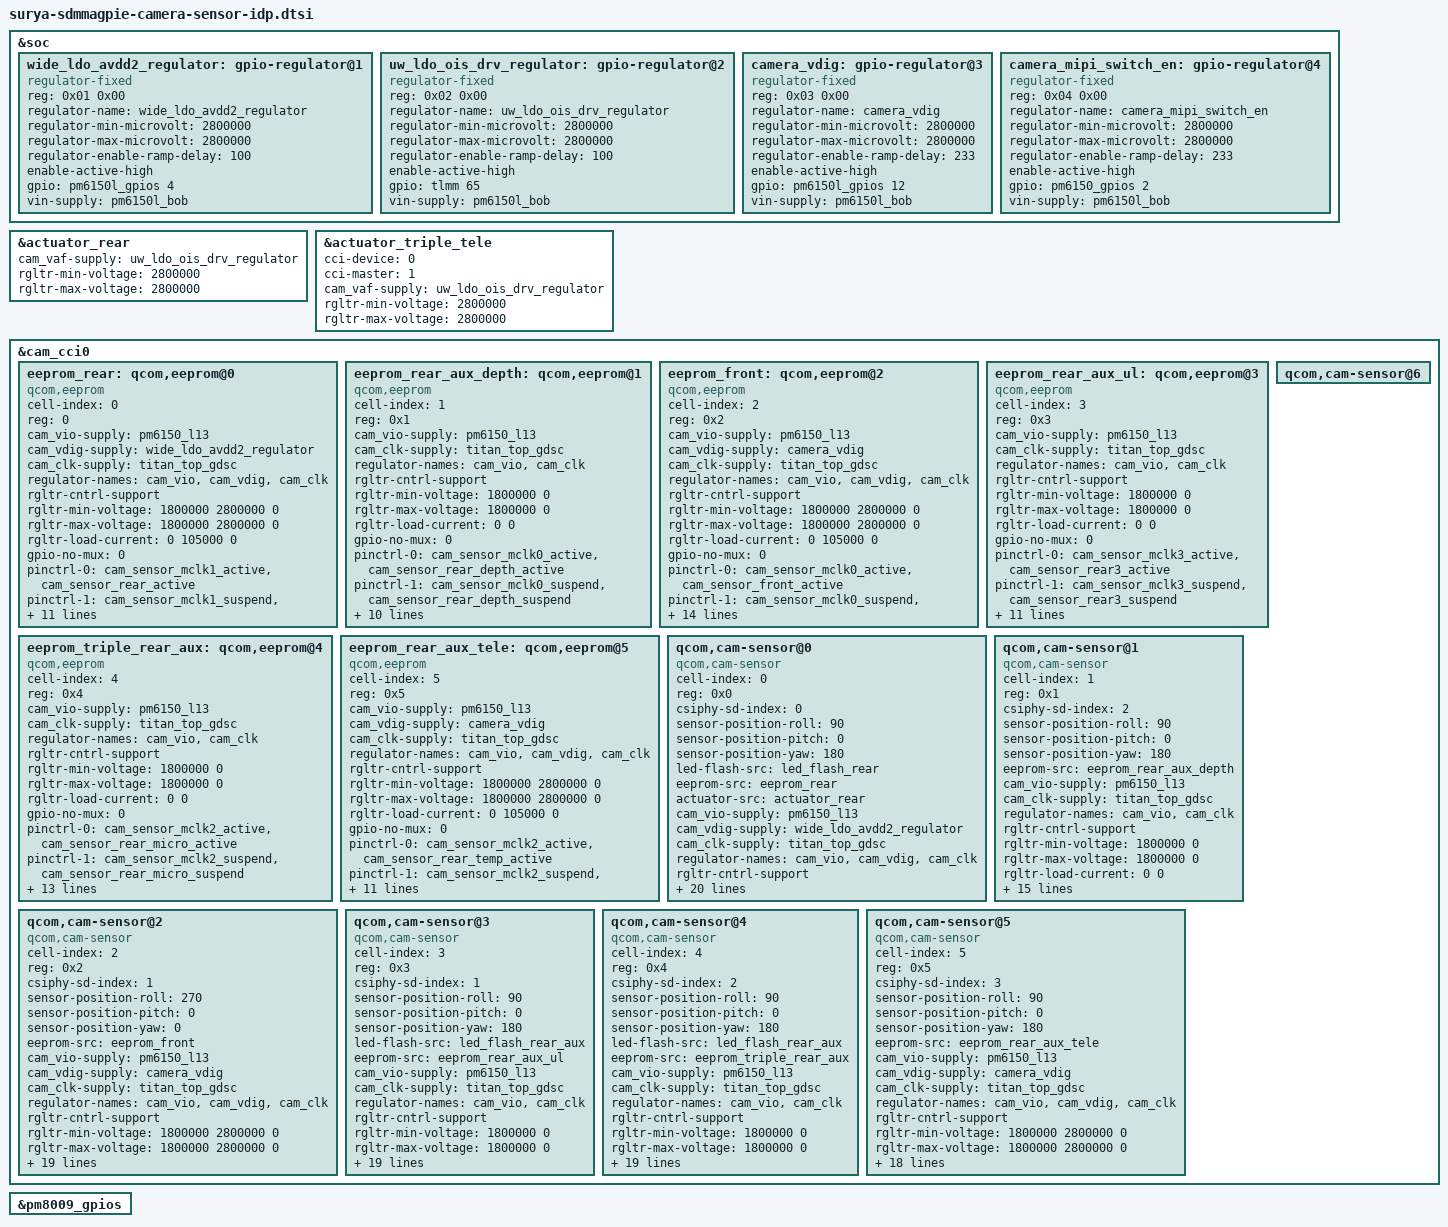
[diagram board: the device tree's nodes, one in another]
&soc {
	wide_ldo_avdd2_regulator: gpio-regulator@1 { /* AVDD2 1.8V */
		compatible = "regulator-fixed";
		reg = <0x01 0x00>;
		regulator-name = "wide_ldo_avdd2_regulator";
		regulator-min-microvolt = <2800000>;
		regulator-max-microvolt = <2800000>;
		regulator-enable-ramp-delay = <100>;
		enable-active-high;
		gpio = <&pm6150l_gpios 4 0>;
		vin-supply = <&pm6150l_bob>; /* pm6150l_s8 */
	};

	uw_ldo_ois_drv_regulator: gpio-regulator@2 { /* drvVDD 2.8V */
		compatible = "regulator-fixed";
		reg = <0x02 0x00>;
		regulator-name = "uw_ldo_ois_drv_regulator";
		regulator-min-microvolt = <2800000>;
		regulator-max-microvolt = <2800000>;
		regulator-enable-ramp-delay = <100>;
		enable-active-high;
		gpio = <&tlmm 65 0>;
		vin-supply = <&pm6150l_bob>;
	};

	camera_vdig: gpio-regulator@3 {
		compatible = "regulator-fixed";
		reg = <0x03 0x00>;
		regulator-name = "camera_vdig";
		regulator-min-microvolt = <2800000>;
		regulator-max-microvolt = <2800000>;
		regulator-enable-ramp-delay = <233>;
		enable-active-high;
		gpio = <&pm6150l_gpios 12 0>;
		vin-supply = <&pm6150l_bob>;
	};

	camera_mipi_switch_en: gpio-regulator@4 {
		compatible = "regulator-fixed";
		reg = <0x04 0x00>;
		regulator-name = "camera_mipi_switch_en";
		regulator-min-microvolt = <2800000>;
		regulator-max-microvolt = <2800000>;
		regulator-enable-ramp-delay = <233>;
		enable-active-high;
		gpio = <&pm6150_gpios 2 0>;
		vin-supply = <&pm6150l_bob>;
	};
};

&actuator_rear {
	cam_vaf-supply = <&uw_ldo_ois_drv_regulator>;
	rgltr-min-voltage = <2800000>;
	rgltr-max-voltage = <2800000>;
};

&actuator_triple_tele {
	cci-device = <0>;
	cci-master = <1>;
	cam_vaf-supply = <&uw_ldo_ois_drv_regulator>;
	rgltr-min-voltage = <2800000>;
	rgltr-max-voltage = <2800000>;
};

&cam_cci0 {
	/delete-node/ qcom,eeprom@0;
	/delete-node/ qcom,eeprom@1;
	/delete-node/ qcom,eeprom@2;
	/delete-node/ qcom,eeprom@3;
	/delete-node/ qcom,eeprom@4;

	eeprom_rear: qcom,eeprom@0 {
		cell-index = <0>;
		reg = <0>;
		compatible = "qcom,eeprom";
		cam_vio-supply = <&pm6150_l13>; /* iovdd 1.8v */
		cam_vdig-supply = <&wide_ldo_avdd2_regulator>; /* dvdd 1.1v */
		cam_clk-supply = <&titan_top_gdsc>;
		regulator-names = "cam_vio", "cam_vdig", "cam_clk";
		rgltr-cntrl-support;
		rgltr-min-voltage = <1800000 2800000 0>;
		rgltr-max-voltage = <1800000 2800000 0>;
		rgltr-load-current = <0 105000 0>;
		gpio-no-mux = <0>;
		pinctrl-names = "cam_default", "cam_suspend";
		pinctrl-0 = <&cam_sensor_mclk1_active
				&cam_sensor_rear_active>;
		pinctrl-1 = <&cam_sensor_mclk1_suspend
				&cam_sensor_rear_suspend>;
		gpios = <&tlmm 14 0>,
			<&tlmm 25 0>;
		gpio-reset = <1>;
		gpio-req-tbl-num = <0 1>;
		gpio-req-tbl-flags = <1 0>;
		gpio-req-tbl-label = "CAMIF_MCLK1",
					"CAM_RESET0";
		sensor-mode = <0>;
		cci-master = <0>;
		status = "ok";
		clocks = <&clock_camcc CAM_CC_MCLK1_CLK>;
		clock-names = "cam_clk";
		clock-cntl-level = "turbo";
		clock-rates = <19200000>;
	};

	eeprom_rear_aux_depth: qcom,eeprom@1 {
		cell-index = <1>;
		reg = <0x1>;
		compatible = "qcom,eeprom";
		cam_vio-supply = <&pm6150_l13>;
		cam_clk-supply = <&titan_top_gdsc>;
		regulator-names = "cam_vio", "cam_clk";
		rgltr-cntrl-support;
		rgltr-min-voltage = <1800000 0>;
		rgltr-max-voltage = <1800000 0>;
		rgltr-load-current = <0 0>;
		gpio-no-mux = <0>;
		pinctrl-names = "cam_default", "cam_suspend";
		pinctrl-0 = <&cam_sensor_mclk0_active
				&cam_sensor_rear_depth_active>;
		pinctrl-1 = <&cam_sensor_mclk0_suspend
				&cam_sensor_rear_depth_suspend>;
		gpios = <&tlmm 13 0>,
				<&tlmm 93 0>;
		gpio-reset = <1>;
		gpio-req-tbl-num = <0 1>;
		gpio-req-tbl-flags = <1 0>;
		gpio-req-tbl-label = "CAMIF_MCLK0",
					"CAM_RESET1";
		sensor-mode = <0>;
		cci-master = <1>;
		status = "ok";
		clocks = <&clock_camcc CAM_CC_MCLK0_CLK>;
		clock-names = "cam_clk";
		clock-cntl-level = "turbo";
		clock-rates = <19200000>;
	};

	eeprom_front: qcom,eeprom@2 {
		cell-index = <2>;
		reg = <0x2>;
		compatible = "qcom,eeprom";
		cam_vio-supply = <&pm6150_l13>;
		cam_vdig-supply = <&camera_vdig>;
		cam_clk-supply = <&titan_top_gdsc>;
		regulator-names = "cam_vio",  "cam_vdig", "cam_clk";
		rgltr-cntrl-support;
		rgltr-min-voltage = <1800000 2800000 0>;
		rgltr-max-voltage = <1800000 2800000 0>;
		rgltr-load-current = <0 105000 0>;
		gpio-no-mux = <0>;
		pinctrl-names = "cam_default", "cam_suspend";
		pinctrl-0 = <&cam_sensor_mclk0_active
				&cam_sensor_front_active>;
		pinctrl-1 = <&cam_sensor_mclk0_suspend
				&cam_sensor_front_suspend>;
		gpios = <&tlmm 13 0>,
			<&tlmm 23 0>,
			<&pm6150_gpios 3 0>;
		gpio-reset = <1>;
		gpio-standby = <2>;
		gpio-req-tbl-num = <0 1 2>;
		gpio-req-tbl-flags = <1 0 0>;
		gpio-req-tbl-label = "CAMIF_MCLK0",
					"CAM_RESET4",
					"CAM_SEL";
		sensor-mode = <0>;
		cci-device = <0>;
		cci-master = <1>;
		status = "ok";
		clocks = <&clock_camcc CAM_CC_MCLK0_CLK>;
		clock-names = "cam_clk";
		clock-cntl-level = "turbo";
		clock-rates = <19200000>;
	};

	eeprom_rear_aux_ul: qcom,eeprom@3 {
		cell-index = <3>;
		reg = <0x3>;
		compatible = "qcom,eeprom";
		cam_vio-supply = <&pm6150_l13>;
		cam_clk-supply = <&titan_top_gdsc>;
		regulator-names = "cam_vio", "cam_clk";
		rgltr-cntrl-support;
		rgltr-min-voltage = <1800000 0>;
		rgltr-max-voltage = <1800000 0>;
		rgltr-load-current = <0 0>;
		gpio-no-mux = <0>;
		pinctrl-names = "cam_default", "cam_suspend";
		pinctrl-0 = <&cam_sensor_mclk3_active
				&cam_sensor_rear3_active>;
		pinctrl-1 = <&cam_sensor_mclk3_suspend
				&cam_sensor_rear3_suspend>;
		gpios = <&tlmm 16 0>,
			<&tlmm 24 0>;
		gpio-reset = <1>;
		gpio-req-tbl-num = <0 1>;
		gpio-req-tbl-flags = <1 0>;
		gpio-req-tbl-label = "CAMIF_MCLK13",
					"CAM_RESET3";
		sensor-mode = <0>;
		cci-device = <1>;
		cci-master = <0>;
		status = "ok";
		clocks = <&clock_camcc CAM_CC_MCLK3_CLK>;
		clock-names = "cam_clk";
		clock-cntl-level = "turbo";
		clock-rates = <19200000>;
	};

	eeprom_triple_rear_aux: qcom,eeprom@4 {
		cell-index = <4>;
		reg = <0x4>;
		compatible = "qcom,eeprom";
		cam_vio-supply = <&pm6150_l13>;
		cam_clk-supply = <&titan_top_gdsc>;
		regulator-names = "cam_vio", "cam_clk";
		rgltr-cntrl-support;
		rgltr-min-voltage = <1800000 0>;
		rgltr-max-voltage = <1800000 0>;
		rgltr-load-current = <0 0>;
		gpio-no-mux = <0>;
		pinctrl-names = "cam_default", "cam_suspend";
		pinctrl-0 = <&cam_sensor_mclk2_active
				&cam_sensor_rear_micro_active>;
		pinctrl-1 = <&cam_sensor_mclk2_suspend
				&cam_sensor_rear_micro_suspend>;
		gpios = <&tlmm 15 0>,
			<&tlmm 64 0>,
			<&tlmm 57 0>;
		gpio-reset = <1>;
		gpio-standby = <2>;
		gpio-req-tbl-num = <0 1 2>;
		gpio-req-tbl-flags = <1 0 0>;
		gpio-req-tbl-label = "CAMIF_MCLK2",
					"CAM_RESET1",
					"CAM_CHIP_EN";
		sensor-mode = <0>;
		cci-device = <1>;
		cci-master = <0>;
		status = "ok";
		clocks = <&clock_camcc CAM_CC_MCLK2_CLK>;
		clock-names = "cam_clk";
		clock-cntl-level = "turbo";
		clock-rates = <19200000>;
	};

	eeprom_rear_aux_tele: qcom,eeprom@5 {
		cell-index = <5>;
		reg = <0x5>;
		compatible = "qcom,eeprom";
		cam_vio-supply = <&pm6150_l13>;
		cam_vdig-supply = <&camera_vdig>;
		cam_clk-supply = <&titan_top_gdsc>;
		regulator-names = "cam_vio", "cam_vdig", "cam_clk";
		rgltr-cntrl-support;
		rgltr-min-voltage = <1800000 2800000 0>;
		rgltr-max-voltage = <1800000 2800000 0>;
		rgltr-load-current = <0 105000 0>;
		gpio-no-mux = <0>;
		pinctrl-names = "cam_default", "cam_suspend";
		pinctrl-0 = <&cam_sensor_mclk2_active
				&cam_sensor_rear_temp_active>;
		pinctrl-1 = <&cam_sensor_mclk2_suspend
				&cam_sensor_rear_temp_suspend>;
		gpios = <&tlmm 15 0>,
			<&tlmm 72 0>;
		gpio-reset = <1>;
		gpio-req-tbl-num = <0 1>;
		gpio-req-tbl-flags = <1 0>;
		gpio-req-tbl-label = "CAMIF_MCLK2",
					"CAM_RESET_N";
		sensor-mode = <0>;
		cci-master = <1>;
		status = "ok";
		clocks = <&clock_camcc CAM_CC_MCLK2_CLK>;
		clock-names = "cam_clk";
		clock-cntl-level = "turbo";
		clock-rates = <19200000>;
	};


	/delete-node/ qcom,cam-sensor@0;
	/delete-node/ qcom,cam-sensor@1;
	/delete-node/ qcom,cam-sensor@2;
	/delete-node/ qcom,cam-sensor@3;
	/delete-node/ qcom,cam-sensor@4;
	/delete-node/ qcom,cam-sensor@5;

	qcom,cam-sensor@0 {
		cell-index = <0>;
		compatible = "qcom,cam-sensor";
		reg = <0x0>;
		csiphy-sd-index = <0>;
		sensor-position-roll = <90>;
		sensor-position-pitch = <0>;
		sensor-position-yaw = <180>;
		led-flash-src = <&led_flash_rear>;
		eeprom-src = <&eeprom_rear>;
		actuator-src = <&actuator_rear>;
		cam_vio-supply = <&pm6150_l13>; /* iovdd 1.8v */
		cam_vdig-supply = <&wide_ldo_avdd2_regulator>; /* dvdd 1.1v */
		cam_clk-supply = <&titan_top_gdsc>;
		regulator-names = "cam_vio", "cam_vdig", "cam_clk";
		rgltr-cntrl-support;
		rgltr-min-voltage = <1800000 2800000 0>;
		rgltr-max-voltage = <1800000 2800000 0>;
		rgltr-load-current = <0 105000 0>;
		gpio-no-mux = <0>;
		pinctrl-names = "cam_default", "cam_suspend";
		pinctrl-0 = <&cam_sensor_mclk1_active
				&cam_sensor_rear_active>;
		pinctrl-1 = <&cam_sensor_mclk1_suspend
				&cam_sensor_rear_suspend>;
		gpios = <&tlmm 14 0>,
			<&tlmm 25 0>,
			<&tlmm 66 0>;
		gpio-reset = <1>;
		gpio-standby = <2>;
		gpio-req-tbl-num = <0 1 2>;
		gpio-req-tbl-flags = <1 0 0>;
		gpio-req-tbl-label = "CAMIF_MCLK1",
					"CAM_RESET0",
					"CAM_STANDBY"; /* vafs */
		sensor-mode = <0>;
		cci-master = <0>;
		status = "ok";
		clocks = <&clock_camcc CAM_CC_MCLK1_CLK>;
		clock-names = "cam_clk";
		clock-cntl-level = "turbo";
		clock-rates = <19200000>;
	};

	qcom,cam-sensor@1 {
		cell-index = <1>;
		compatible = "qcom,cam-sensor";
		reg = <0x1>;
		csiphy-sd-index = <2>;
		sensor-position-roll = <90>;
		sensor-position-pitch = <0>;
		sensor-position-yaw = <180>;
		eeprom-src = <&eeprom_rear_aux_depth>;
		cam_vio-supply = <&pm6150_l13>;
		cam_clk-supply = <&titan_top_gdsc>;
		regulator-names = "cam_vio",
			"cam_clk";
		rgltr-cntrl-support;
		rgltr-min-voltage = <1800000 0>;
		rgltr-max-voltage = <1800000 0>;
		rgltr-load-current = <0 0>;
		gpio-no-mux = <0>;
		pinctrl-names = "cam_default", "cam_suspend";
		pinctrl-0 = <&cam_sensor_mclk0_active
				&cam_sensor_rear_depth_active>;
		pinctrl-1 = <&cam_sensor_mclk0_suspend
				&cam_sensor_rear_depth_suspend>;
		gpios = <&tlmm 13 0>,
				<&tlmm 93 0>;
		gpio-reset = <1>;
		gpio-req-tbl-num = <0 1>;
		gpio-req-tbl-flags = <1 0>;
		gpio-req-tbl-label = "CAMIF_MCLK0",
					"CAM_RESET1";
		sensor-mode = <0>;
		cci-master = <1>;
		status = "ok";
		clocks = <&clock_camcc CAM_CC_MCLK0_CLK>;
		clock-names = "cam_clk";
		clock-cntl-level = "turbo";
		clock-rates = <19200000>;
	};

	qcom,cam-sensor@2 {
		cell-index = <2>;
		compatible = "qcom,cam-sensor";
		reg = <0x2>;
		csiphy-sd-index = <1>;
		sensor-position-roll = <270>;
		sensor-position-pitch = <0>;
		sensor-position-yaw = <0>;
		eeprom-src = <&eeprom_front>;
		cam_vio-supply = <&pm6150_l13>;
		cam_vdig-supply = <&camera_vdig>; /* gpio12 */
		cam_clk-supply = <&titan_top_gdsc>;
		regulator-names = "cam_vio",  "cam_vdig", "cam_clk";
		rgltr-cntrl-support;
		rgltr-min-voltage = <1800000 2800000 0>;
		rgltr-max-voltage = <1800000 2800000 0>;
		rgltr-load-current = <0 105000 0>;
		gpio-no-mux = <0>;
		pinctrl-names = "cam_default", "cam_suspend";
		pinctrl-0 = <&cam_sensor_mclk0_active
				&cam_sensor_front_active>;
		pinctrl-1 = <&cam_sensor_mclk0_suspend
				&cam_sensor_front_suspend>;
		gpios = <&tlmm 13 0>,
			<&tlmm 23 0>,
			<&pm6150_gpios 3 0>;
		gpio-reset = <1>;
		gpio-standby = <2>;
		gpio-req-tbl-num = <0 1 2>;
		gpio-req-tbl-flags = <1 0 0>;
		gpio-req-tbl-label = "CAMIF_MCLK0",
					"CAM_RESET4",
					"CAM_SEL";
		sensor-mode = <0>;
		cci-device = <0>;
		cci-master = <1>;
		status = "ok";
		clocks = <&clock_camcc CAM_CC_MCLK0_CLK>;
		clock-names = "cam_clk";
		clock-cntl-level = "turbo";
		clock-rates = <19200000>;
	};

	qcom,cam-sensor@3 {
		cell-index = <3>;
		compatible = "qcom,cam-sensor";
		reg = <0x3>;
		csiphy-sd-index = <1>;
		sensor-position-roll = <90>;
		sensor-position-pitch = <0>;
		sensor-position-yaw = <180>;
		led-flash-src = <&led_flash_rear_aux>;
		eeprom-src = <&eeprom_rear_aux_ul>;
		cam_vio-supply = <&pm6150_l13>;
		cam_clk-supply = <&titan_top_gdsc>;
		regulator-names = "cam_vio", "cam_clk";
		rgltr-cntrl-support;
		rgltr-min-voltage = <1800000 0>;
		rgltr-max-voltage = <1800000 0>;
		rgltr-load-current = <0 0>;
		gpio-no-mux = <0>;
		pinctrl-names = "cam_default", "cam_suspend";
		pinctrl-0 = <&cam_sensor_mclk3_active
				&cam_sensor_rear3_active>;
		pinctrl-1 = <&cam_sensor_mclk3_suspend
				&cam_sensor_rear3_suspend>;
		gpios = <&tlmm 16 0>,
				<&tlmm 24 0>,
				<&pm6150_gpios 3 0>;
		gpio-reset = <1>;
		gpio-standby = <2>;
		gpio-req-tbl-num = <0 1 2>;
		gpio-req-tbl-flags = <1 0 0>;
		gpio-req-tbl-label = "CAMIF_MCLK3",
					"CAM_RESET3",
					"CAM_SEL";
		sensor-mode = <0>;
		cci-device = <1>;
		cci-master = <0>;
		status = "ok";
		clocks = <&clock_camcc CAM_CC_MCLK3_CLK>;
		clock-names = "cam_clk";
		clock-cntl-level = "turbo";
		clock-rates = <19200000>;
	};

	qcom,cam-sensor@4 {
		cell-index = <4>;
		compatible = "qcom,cam-sensor";
		reg = <0x4>;
		csiphy-sd-index = <2>;
		sensor-position-roll = <90>;
		sensor-position-pitch = <0>;
		sensor-position-yaw = <180>;
		led-flash-src = <&led_flash_rear_aux>;
		eeprom-src = <&eeprom_triple_rear_aux>;
		cam_vio-supply = <&pm6150_l13>;
		cam_clk-supply = <&titan_top_gdsc>;
		regulator-names = "cam_vio", "cam_clk";
		rgltr-cntrl-support;
		rgltr-min-voltage = <1800000 0>;
		rgltr-max-voltage = <1800000 0>;
		rgltr-load-current = <0 0>;
		gpio-no-mux = <0>;
		pinctrl-names = "cam_default", "cam_suspend";
		pinctrl-0 = <&cam_sensor_mclk2_active
				&cam_sensor_rear_micro_active>;
		pinctrl-1 = <&cam_sensor_mclk2_suspend
				&cam_sensor_rear_micro_suspend>;
		gpios = <&tlmm 15 0>,
			<&tlmm 64 0>,
			<&tlmm 57 0>;
		gpio-reset = <1>;
		gpio-standby = <2>; /* chip-en */
		gpio-req-tbl-num = <0 1 2>;
		gpio-req-tbl-flags = <1 0 0>;
		gpio-req-tbl-label = "CAMIF_MCLK2",
					"CAM_RESET1",
					"CAM_CHIP_EN";
		sensor-mode = <0>;
		cci-device = <1>;
		cci-master = <0>;
		status = "ok";
		clocks = <&clock_camcc CAM_CC_MCLK2_CLK>;
		clock-names = "cam_clk";
		clock-cntl-level = "turbo";
		clock-rates = <19200000>;
	};

	qcom,cam-sensor@5 {
		cell-index = <5>;
		compatible = "qcom,cam-sensor";
		reg = <0x5>;
		csiphy-sd-index = <3>;
		sensor-position-roll = <90>;
		sensor-position-pitch = <0>;
		sensor-position-yaw = <180>;
		eeprom-src = <&eeprom_rear_aux_tele>;
		cam_vio-supply = <&pm6150_l13>;
		cam_vdig-supply = <&camera_vdig>;
		cam_clk-supply = <&titan_top_gdsc>;
		regulator-names = "cam_vio", "cam_vdig", "cam_clk";
		rgltr-cntrl-support;
		rgltr-min-voltage = <1800000 2800000 0>;
		rgltr-max-voltage = <1800000 2800000 0>;
		rgltr-load-current = <0 105000 0>;
		gpio-no-mux = <0>;
		pinctrl-names = "cam_default", "cam_suspend";
		pinctrl-0 = <&cam_sensor_mclk2_active
				&cam_sensor_rear_temp_active>;
		pinctrl-1 = <&cam_sensor_mclk2_suspend
				&cam_sensor_rear_temp_suspend>;
		gpios = <&tlmm 15 0>,
			<&tlmm 72 0>,
			<&tlmm 88 0>;
		gpio-reset = <1>;
		gpio-standby = <2>; /* vaf1 */
		gpio-req-tbl-num = <0 1 2>;
		gpio-req-tbl-flags = <1 0 0>;
		gpio-req-tbl-label = "CAMIF_MCLK2",
					"CAM_RESET_N",
					"CAM_STANDBY"; /* vafs */
		sensor-mode = <0>;
		cci-master = <1>;
		status = "ok";
		clocks = <&clock_camcc CAM_CC_MCLK2_CLK>;
		clock-names = "cam_clk";
		clock-cntl-level = "turbo";
		clock-rates = <19200000>;
	};

	qcom,cam-sensor@6 {
		/delete-property/ eeprom-src;
	};
};

&pm8009_gpios {
	/delete-node/ cam_sensor_rear_active;
	/delete-node/ cam_sensor_rear_suspend;
	/delete-node/ cam_sensor_front_active;
	/delete-node/ cam_sensor_front_suspend;
};
